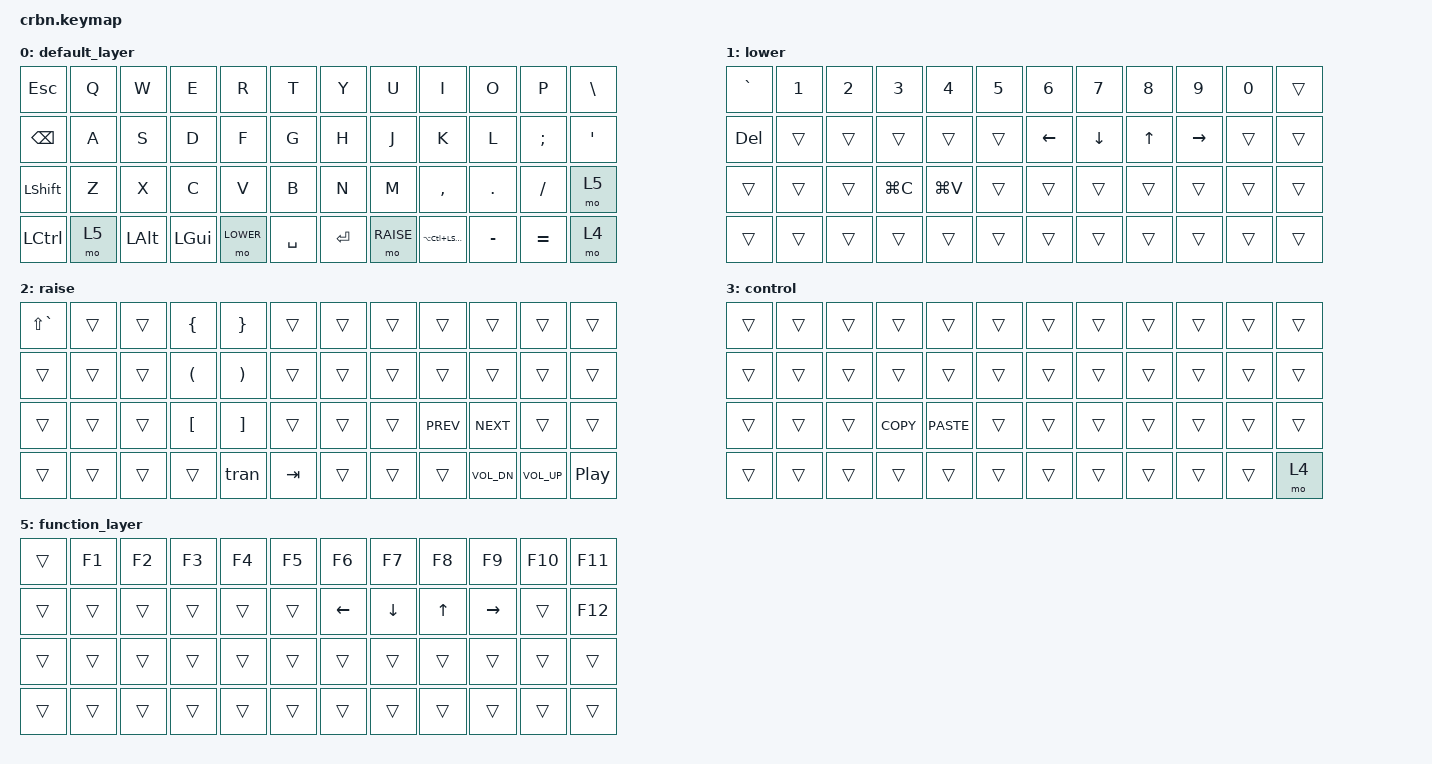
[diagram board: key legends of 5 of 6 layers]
/*
 * Copyright (c) 2020 The ZMK Contributors
 *
 * SPDX-License-Identifier: MIT
 */

#include <behaviors.dtsi>
#include <dt-bindings/zmk/keys.h>
#include <dt-bindings/zmk/bt.h>

#define NONE 0
#define LOWER 1
#define RAISE 2
#define SOME_THING 4 // need to update this layer what should this be called??
#define MEDIA 5
#define FUNC 6

/ {
	keymap {
		compatible = "zmk,keymap";

		default_layer {
				// -----------------------------------------------------------------------------------------
				// |  ESC    |  Q   |  W   |  E   |  R   |  T    |   Y   |  U    |  I   |  O   |   P   |  \    |
				// |  BSPC   |  A   |  S   |  D   |  F   |  G    |   H   |  J    |  K   |  L   |   ;   |  '    |
				// | SHIFT   |  Z   |  X   |  C   |  V   |  B    |   N   |  M    |  ,   |  .   |   /   |  Mo5  |
				// | LCTRL   |  FN  | LALT | LGUI | LOWR | SPACE |  RET  |  RAIS | MEH  |  -   |   =   |  Mo4  |
			bindings = <
				&kp ESC    &kp Q     &kp W    &kp E    &kp R     &kp T     &kp Y     &kp U      &kp I             &kp O     &kp P     &kp BSLH
				&kp BSPC   &kp A     &kp S    &kp D    &kp F     &kp G     &kp H     &kp J      &kp K             &kp L     &kp SEMI  &kp SQT
				&kp LSHFT  &kp Z     &kp X    &kp C    &kp V     &kp B     &kp N     &kp M      &kp COMMA         &kp DOT   &kp FSLH  &mo 5
				&kp LCTRL  &mo 5     &kp LALT &kp LGUI &mo LOWER &kp SPACE &kp RET   &mo RAISE  &kp LA(LC(LSHFT)) &kp MINUS &kp EQUAL &mo 4
			>;

			// sensor-bindings = <&inc_dec_kp PG_UP PG_DN>;
		};

		lower {
				// -----------------------------------------------------------------------------------------
				// |     |  1   |  2   |  3    |  4    |  5    |  6   |  7    |  8  | 9     |   0   |      |
				// | DEL |      |      |       |       |       | LEFT | DOWN  | UP  | RIGHT |       |      |
				// |     |      |      | COPY  | PASTE |       |      |       |     |       |       |      |
				// |     |      |      |       |       |       |      |       |     |       |       |      |
			bindings = <
				&kp GRAVE  &kp N1  &kp N2  &kp N3     &kp N4      &kp N5   &kp N6    &kp N7    &kp N8    &kp N9     &kp N0    &trans
				&kp DEL    &trans  &trans  &trans     &trans      &trans   &kp LEFT  &kp DOWN  &kp UP    &kp RIGHT  &trans    &trans
				&trans     &trans  &trans  &kp LG(C)  &kp LG(V)   &trans   &trans    &trans    &trans    &trans     &trans    &trans
				&trans     &trans  &trans  &trans     &trans      &trans   &trans    &trans    &trans    &trans     &trans    &trans
			>;

			// sensor-bindings = <&inc_dec_kp C_VOL_UP C_VOL_DN>;
		};

		raise {
				// -----------------------------------------------------------------------------------------
				// | LS(GRAVE) |    |    |  {   |  }   |     |      |       |       |          |        |      |
				// |           |    |    |  (   |  )   |     |      |       |       |          |        |      |
				// |           |    |    |  [   |  ]   |     |      |       | PREV  |  Next    |        |      |
				// |           |    |    |      |      | TAB |      |       |       | VOL_DOWN | VOL_UP | PLAY |
			bindings = <
				&kp LS(GRAVE) &trans &trans &kp LBRC &kp RBRC &trans  &trans    &trans    &trans      &trans       &trans       &trans
				&trans        &trans &trans &kp LPAR &kp RPAR &trans  &trans    &trans    &trans      &trans       &trans       &trans
				&trans        &trans &trans &kp LBKT &kp RBKT &trans  &trans    &trans    &kp C_PREV  &kp C_NEXT   &trans       &trans
				&trans        &trans &trans &trans   &tran    &kp TAB &trans    &trans    &trans      &kp C_VOL_DN &kp C_VOL_UP &kp C_PP
			>;
		};

		control {
			bindings = <
				&trans &trans &trans &trans     &trans      &trans &trans &trans &trans &trans &trans &trans
				&trans &trans &trans &trans     &trans      &trans &trans &trans &trans &trans &trans &trans
				&trans &trans &trans &kp K_COPY &kp K_PASTE &trans &trans &trans &trans &trans &trans &trans
				&trans &trans &trans &trans     &trans      &trans &trans &trans &trans &trans &trans &mo 4
			>;
		};

		SOME_THING {
			bindings = <
				&bootloader &reset  &trans  &trans   &trans  &trans  &trans  &kp N6    &kp N8    &kp N9    &trans
				&trans      &trans  &trans  &trans   &trans  &trans  &trans  &kp N4    &kp N5    &kp N6    &trans
				&trans      &trans  &trans  &trans   &trans  &trans  &trans  &kp N1    &kp N2    &kp N3    &trans
				&trans      &trans  &trans  &trans   &trans  &trans  &trans  &trans    &kp N0    &trans    &trans
			>;
		};

		function_layer {
				// -----------------------------------------------------------------------------------------
				// |      |  F1  |  F2  |  F3  |  F4  |  F5  |  F6  |  F7  |  F8  |  F9   |  F10  |  F11  |
				// |      |      |      |      |      |      | LEFT | DOWN |  UP  | RIGHT |       |  F12  |
				// |      |      |      |      |      |      |      |      |      |       |       |       |
				// |      |      |      |      |      |      |      |      |      |       |       |       |
			bindings = <
				&trans &kp F1 &kp F2 &kp F3 &kp F4 &kp F5 &kp F6   &kp F7   &kp F8 &kp F9    &kp F10 &kp F11
				&trans &trans &trans &trans &trans &trans &kp LEFT &kp DOWN &kp UP &kp RIGHT &trans  &kp F12
				&trans &trans &trans &trans &trans &trans &trans   &trans   &trans &trans    &trans  &trans
				&trans &trans &trans &trans &trans &trans &trans   &trans   &trans &trans    &trans  &trans
			>;
		};
	};
};
